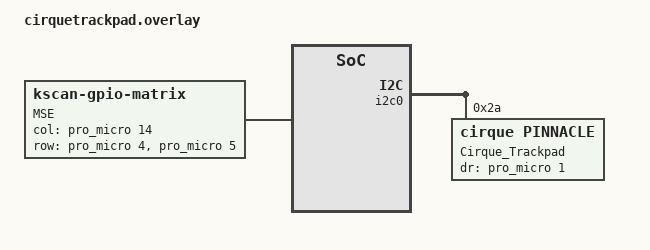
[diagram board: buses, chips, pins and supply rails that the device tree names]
// cirquetrackpad.overlay
 #include <dt-bindings/zmk/matrix_transform.h>


/ {
    chosen {
        zmk,kscan = &default_kscan;
        zmk,matrix_transform = &default_transform;
    };

    default_transform: keymap_transform_0 {
        compatible = "zmk,matrix-transform";
        columns = <1>;
        rows = <2>;
        // | SW1 |
        // | SW2 | 
        map = <
            RC(0,0)
            RC(1,0)
        >;
    };

    default_kscan: kscan {
        compatible = "zmk,kscan-gpio-matrix";
        label = "MSE";
        diode-direction = "col2row";
        col-gpios = <&pro_micro 14 GPIO_ACTIVE_HIGH>;
        row-gpios = <&pro_micro 4 (GPIO_ACTIVE_HIGH | GPIO_PULL_DOWN)>
                  , <&pro_micro 5 (GPIO_ACTIVE_HIGH | GPIO_PULL_DOWN)>;

    };
};

&i2c0 {
    status = "okay";
    trackpad@2a {
	    compatible = "cirque,pinnacle";
        dr-gpios = <&pro_micro 1 GPIO_ACTIVE_HIGH>;
	    reg = <0x2a>;
	    label = "Cirque_Trackpad";
	    rotate-90;
	    //sleep;
	    //no-taps;
    };
};
